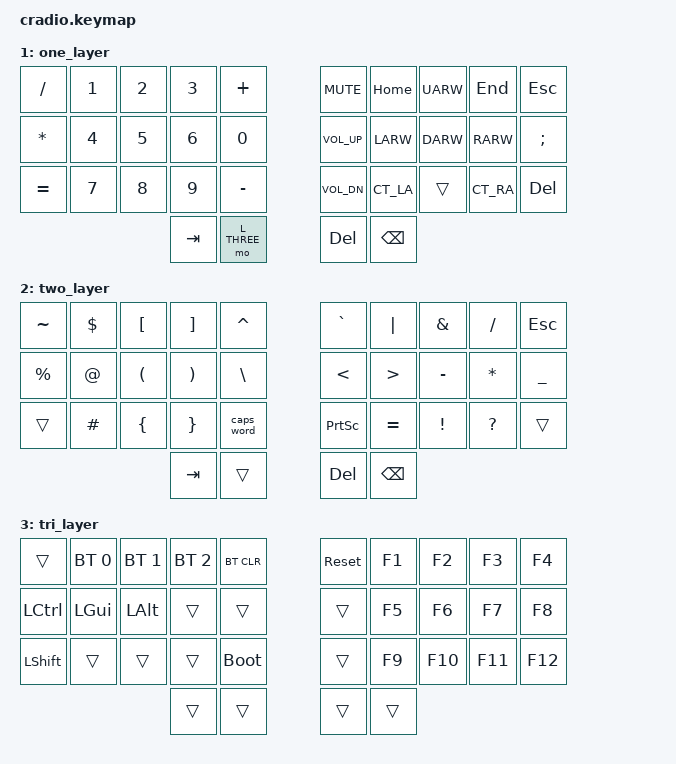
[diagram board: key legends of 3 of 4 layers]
// Copyright (c) 2022 The ZMK Contributors
// SPDX-License-Identifier: MIT

#include <behaviors.dtsi>
#include <dt-bindings/zmk/keys.h>
#include <dt-bindings/zmk/bt.h>

// Define Layer Names
#define L_MAIN  0
#define L_ONE   1
#define L_TWO   2
#define L_THREE 3

// Home row mods macro - usage example: HRMR(N,        E,         I,        O)
#define HRML(k1,k2,k3,k4) &ht LSHFT k1  &ht LALT k2  &ht LCTRL k3  &ht LGUI k4
#define HRMR(k1,k2,k3,k4) &ht RGUI k1  &ht RCTRL k2  &ht RALT k3  &ht RSHFT k4

// Thumb row layer macro
#define TRLR(k1,k2,k3,k4) &lt L_TWO k1	&lt L_ONE k2	&lt L_ONE k3	&lt L_TWO k4

// ************************
// MACRO DEFINITIONS
// ************************
/ {
    macros {
        copy_macro: copy_macro {
            label = "ZM_copy_macro";
            compatible = "zmk,behavior-macro";
            #binding-cells = <0>;
            bindings
                = <&macro_press &kp LCTRL>
                , <&macro_tap &kp C>
                , <&macro_release &kp LCTRL>
                ;
        };
		
		paste_macro: paste_macro {
            label = "ZM_paste_macro";
            compatible = "zmk,behavior-macro";
            #binding-cells = <0>;
            bindings
                = <&macro_press &kp LCTRL>
                , <&macro_tap &kp V>
                , <&macro_release &kp LCTRL>
                ;
        };
		
		cut_macro: cut_macro {
            label = "ZM_cut_macro";
            compatible = "zmk,behavior-macro";
            #binding-cells = <0>;
            bindings
                = <&macro_press &kp LCTRL>
                , <&macro_tap &kp X>
                , <&macro_release &kp LCTRL>
                ;
        };
		
		select_all_macro: select_all_macro {
            label = "ZM_select_all_macro";
            compatible = "zmk,behavior-macro";
            #binding-cells = <0>;
            bindings
                = <&macro_press &kp LCTRL>
                , <&macro_tap &kp A>
                , <&macro_release &kp LCTRL>
                ;
        };
		
		
		ctrl_shift_esc_macro: ctrl_shift_esc_macro {
            label = "ZM_ctrl_shift_esc_macro";
            compatible = "zmk,behavior-macro";
            #binding-cells = <0>;
            bindings
                = <&macro_press &kp LCTRL>
                , <&macro_press &kp LSHFT>
                , <&macro_press &kp ESC>
                , <&macro_release &kp LCTRL>
                , <&macro_release &kp LSHFT>
                , <&macro_release &kp ESC>
                ;
        };
		
		ctrl_alt_del_macro: ctrl_alt_del_macro {
            label = "ZM_ctrl_alt_del_macro";
            compatible = "zmk,behavior-macro";
            #binding-cells = <0>;
            bindings
                = <&macro_press &kp LCTRL>
                , <&macro_press &kp LALT>
                , <&macro_press &kp DEL>
                , <&macro_release &kp LCTRL>
                , <&macro_release &kp LALT>
                , <&macro_release &kp DEL>
                ;
        };
		
		CT_LA: ctrl_left_arrow_macro {
            label = "ZM_ctrl_left_arrow_macro";
            compatible = "zmk,behavior-macro";
            #binding-cells = <0>;
            bindings
                = <&macro_press &kp LCTRL>
                , <&macro_tap &kp LARW>
                , <&macro_release &kp LCTRL>
                ;
        };
		
		CT_RA: ctrl_right_arrow_macro {
            label = "ZM_ctrl_right_arrow_macro";
            compatible = "zmk,behavior-macro";
            #binding-cells = <0>;
            bindings
                = <&macro_press &kp LCTRL>
                , <&macro_tap &kp RARW>
                , <&macro_release &kp LCTRL>
                ;
        };
		
		undo_macro: undo_macro {
            label = "ZM_undo_macro";
            compatible = "zmk,behavior-macro";
            #binding-cells = <0>;
            bindings
                = <&macro_press &kp LCTRL>
                , <&macro_tap &kp Z>
                , <&macro_release &kp LCTRL>
                ;
        };
		
		redo_macro: redo_macro {
            label = "ZM_redo_macro";
            compatible = "zmk,behavior-macro";
            #binding-cells = <0>;
            bindings
                = <&macro_press &kp LCTRL>
                , <&macro_tap &kp Y>
                , <&macro_release &kp LCTRL>
                ;
        };
		
    };
};


// ************************
// COMBO DEFINITIONS
// ************************
/ {
    combos {
        compatible = "zmk,combos";
		
		combo_space {
            timeout-ms = <50>;
            key-positions = <11 12 13>;
            bindings = <&kp SPACE>;
        };
		
        combo_colon {
            timeout-ms = <50>;
            key-positions = <12 13>;
            bindings = <&kp COLON>;
        };
		
		combo_semicolon {
            timeout-ms = <50>;
            key-positions = <11 13>;
            bindings = <&kp SEMICOLON>;
        };
		
		combo_ctrl_shft_esc {
            timeout-ms = <50>;
            key-positions = <0 10 20>;
            bindings = <&ctrl_shift_esc_macro>;
        };
		
		combo_ctrl_alt_del {
            timeout-ms = <50>;
            key-positions = <9 19 29>;
            bindings = <&ctrl_alt_del_macro>;
        };
		
		combo_printscreen {
            timeout-ms = <50>;
            key-positions = <26 27>;
            bindings = <&kp PSCRN>;
        };
		
		combo_Y {
            timeout-ms = <50>;
            key-positions = <26 28>;
            bindings = <&kp SEMICOLON>;
        };
		
    };
};

// ************************
// KEYBOARD SETUP
// ************************
/ {
	// ************************
	// BEHAVIOR DEFINITIONS
	// ************************
    behaviors {
        ht: hold_tap {
            label = "hold_tap";
            compatible = "zmk,behavior-hold-tap";
            #binding-cells = <2>;
            flavor = "tap-preferred";
            tapping-term-ms = <270>;
            quick-tap-ms = <200>;
            global-quick-tap;
            bindings = <&kp>, <&kp>;
        };
		
		td_copy: tap_dance_copy {
            compatible = "zmk,behavior-tap-dance";
            label = "TAP_DANCE_COPY";
            #binding-cells = <0>;
            tapping-term-ms = <200>;
            bindings = <&kp C>, <&copy_macro>;
        };
		
		td_paste: tap_dance_paste {
            compatible = "zmk,behavior-tap-dance";
            label = "TAP_DANCE_PASTE";
            #binding-cells = <0>;
            tapping-term-ms = <200>;
            bindings = <&kp W>, <&paste_macro>;
        };
		
		td_cut: tap_dance_cut {
            compatible = "zmk,behavior-tap-dance";
            label = "TAP_DANCE_CUT";
            #binding-cells = <0>;
            tapping-term-ms = <200>;
            bindings = <&kp B>, <&cut_macro>;
        };
		
		td_select_all: tap_dance_select_all {
            compatible = "zmk,behavior-tap-dance";
            label = "TAP_DANCE_SELECT_ALL";
            #binding-cells = <0>;
            tapping-term-ms = <200>;
            bindings = <&kp V>, <&select_all_macro>;
        };
		
		td_undo: tap_dance_undo {
            compatible = "zmk,behavior-tap-dance";
            label = "TAP_DANCE_UNDO";
            #binding-cells = <0>;
            tapping-term-ms = <200>;
            bindings = <&kp X>, <&undo_macro>;
        };
		
		td_redo: tap_dance_redo {
            compatible = "zmk,behavior-tap-dance";
            label = "TAP_DANCE_REDO";
            #binding-cells = <0>;
            tapping-term-ms = <200>;
            bindings = <&kp R>, <&redo_macro>;
        };
    };

    //conditional_layers {
    //    compatible = "zmk,conditional-layers";
    //    tri_layer {
    //        if-layers = <1 2>;
    //        then-layer = <3>;
    //    };
    //};


	// ************************
	// KEY MAP DEFINITION
	// ************************
    keymap {
        compatible = "zmk,keymap";
		
        hands_down_gold_layer {
            bindings = <
        //╭──────────┬──────────┬──────────┬──────────┬──────────╮   ╭──────────┬──────────┬──────────┬──────────┬──────────╮
        //│  J       │  G       │  M       │  P       │  V       │   │  Z       │  / ?     │  .       │  ' "     │ ESCAPE   │
           &kp J       &kp G      &kp M      &kp P    &td_select_all   &kp Z      &kp SLASH  &kp DOT   &kp APOS    &kp ESC
        //├──────────┼──────────┼──────────┼──────────┼──────────┤   ├──────────┼──────────┼──────────┼──────────┼──────────┤
        //│  R       │  S       │  N       │  D       │  B       │   │  ,       │  A       │  E       │  I       │  H       │
          &ht LCTRL R &ht LGUI S &ht LSHFT N  &kp D    &td_cut         &kp COMMA  &kp A    &ht RSHFT E &ht RGUI I &ht RCTRL H
        //├──────────┼──────────┼──────────┼──────────┼──────────┤   ├──────────┼──────────┼──────────┼──────────┼──────────┤
        //│  X       │  F       │  L       │  C       │  W       │   │  Q       │  U       │  O       │  Y       │  K       │
           &td_undo    &ht LALT F &kp L      &td_copy   &td_paste      &kp Q      &kp U      &kp O      &kp Y      &ht LALT K
        //╰──────────┴──────────┴──────────┼──────────┼──────────┤   ├──────────┼──────────┼──────────┴──────────┴──────────╯
        //								   | to lay2  | to lay1  |   |  to lay1 |  to lay2 |
										TRLR( T ,        BSPC,          ENTER,     SPACE)
        //                                 ╰──────────┴──────────╯   ╰──────────┴──────────╯
            >;
        };
		

        one_layer {
            bindings = <
        //╭──────────┬──────────┬──────────┬──────────┬──────────╮   ╭──────────┬──────────┬──────────┬──────────┬──────────╮
        //│  /       │  1       │  2       │  3       │  +       │   │ MUTE     │ HOME     │ UP       │ END      │ ESCAPE   │
            &kp SLASH  &kp N1     &kp N2     &kp N3     &kp PLUS      &kp C_MUTE  &kp HOME   &kp UARW   &kp END    &kp ESC
        //├──────────┼──────────┼──────────┼──────────┼──────────┤   ├──────────┼──────────┼──────────┼──────────┼──────────┤
        //│  *       │  4       │  5       │  6       │  0       │   │ VOL UP   │ LEFT     │ DOWN     │ RIGHT    │ SEMI     │
            &kp ASTRK  &kp N4     &kp N5     &kp N6     &kp N0       &kp C_VOL_UP &kp LARW   &kp DARW    &kp RARW  &kp SEMI
        //├──────────┼──────────┼──────────┼──────────┼──────────┤   ├──────────┼──────────┼──────────┼──────────┼──────────┤
        //│  =       │  7       │  8       │  9       │  -       │   │ VOL DOWN │ CTRL LEFT│          │CTRL RIGHT│ DELETE   │
           &kp EQUAL   &kp N7     &kp N8     &kp N9     &kp MINUS    &kp C_VOL_DN &CT_LA     &trans     &CT_RA     &kp DEL
        //╰──────────┴──────────┴──────────┼──────────┼──────────┤   ├──────────┼──────────┼──────────┴──────────┴──────────╯
                                             &kp TAB   &mo L_THREE     &kp DEL    &kp BSPC
        //                                 ╰──────────┴──────────╯   ╰──────────┴──────────╯
            >;
        };

        two_layer {
            bindings = <
        //╭──────────┬──────────┬──────────┬──────────┬──────────╮   ╭──────────┬──────────┬──────────┬──────────┬──────────╮
        //│    ~     │  $       │  [       │  ]       │   ^      │   │  `       │   |      │  &       │   /      │ ESCAPE   │
            &kp TILDE &kp DOLLAR  &kp LBKT   &kp RBKT   &kp CARET     &kp GRAVE  &kp PIPE   &kp AMPS   &kp SLASH   &kp ESC
        //├──────────┼──────────┼──────────┼──────────┼──────────┤   ├──────────┼──────────┼──────────┼──────────┼──────────┤
        //│  %       │  @       │  (       │  )       │  \       │   │  <       │  >       │  -       │  *       │  _       │
            &kp PRCNT  &kp AT     &kp LPAR   &kp RPAR   &kp BSLH       &kp LT     &kp GT     &kp MINUS  &kp STAR   &kp UNDER
        //├──────────┼──────────┼──────────┼──────────┼──────────┤   ├──────────┼──────────┼──────────┼──────────┼──────────┤
        //│          │  #       │  {       │  }       │  CAPS    │   │ PRNT SCRN│  =       │  !       │  ?       │          |
            &trans     &kp POUND  &kp LBRC   &kp RBRC  &caps_word      &kp PSCRN  &kp EQUAL  &kp EXCL   &kp QMARK  &trans 
        //╰──────────┴──────────┴──────────┼──────────┼──────────┤   ├──────────┼──────────┼──────────┴──────────┴──────────╯
                                             &kp TAB    &trans         &kp DEL    &kp BSPC
        //                                 ╰──────────┴──────────╯   ╰──────────┴──────────╯
            >;
        };

        tri_layer {
            bindings = <
        //╭──────────┬──────────┬──────────┬──────────┬──────────╮   ╭──────────┬──────────┬──────────┬──────────┬──────────╮
        //│          │ PROFILE 0│ PROFILE 1│ PROFILE 2│ CLEAR BT │   │  RESET   │ FUNC 1   │ FUNC 2   │ FUNC 3   │ FUNC 4   │
            &trans &bt BT_SEL 0 &bt BT_SEL 1 &bt BT_SEL 2 &bt BT_CLR  &sys_reset  &kp F1     &kp F2     &kp F3     &kp F4
        //├──────────┼──────────┼──────────┼──────────┼──────────┤   ├──────────┼──────────┼──────────┼──────────┼──────────┤
        //│  CTRL    │  LGUI    │  ALT     │          │          │   │          │ FUNC 5   │ FUNC 6   │ FUNC 7   │ FUNC 8   │
           &kp LCTRL   &kp LGUI   &kp LALT   &trans     &trans         &trans     &kp F5     &kp F6     &kp F7     &kp F8
        //├──────────┼──────────┼──────────┼──────────┼──────────┤   ├──────────┼──────────┼──────────┼──────────┼──────────┤
        //│ SHIFT    │          │          │          │BOOTLOADER│   │          │ FUNC 9   │ FUNC 10  │ FUNC 11  │ FUNC 12  │
            &kp LSHFT  &trans     &trans     &trans    &bootloader     &trans     &kp F9     &kp F10    &kp F11    &kp F12
        //╰──────────┴──────────┴──────────┼──────────┼──────────┤   ├──────────┼──────────┼──────────┴──────────┴──────────╯
                                             &trans     &trans         &trans     &trans
        //                                 ╰──────────┴──────────╯   ╰──────────┴──────────╯
            >;
        };
    };
};
